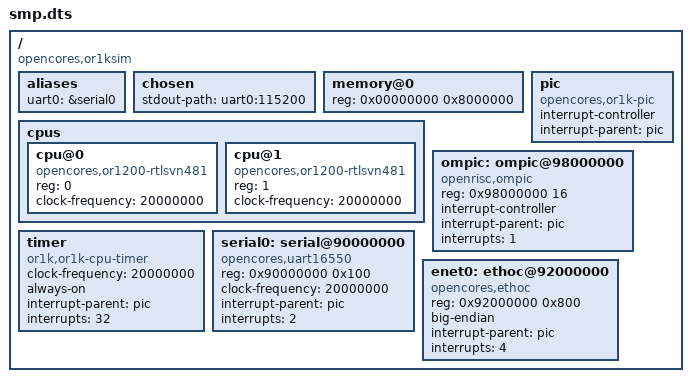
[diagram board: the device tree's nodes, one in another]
/dts-v1/;

/ {
    compatible = "opencores,or1ksim";

    #address-cells = <1>;
    #size-cells = <1>;

    aliases {
        uart0 = &serial0;
    };

    chosen {
        stdout-path = "uart0:115200";
    };

    memory@0 {
        device_type = "memory";
        reg = <0x00000000 0x8000000>;
    };

    cpus {
        #address-cells = <1>;
        #size-cells = <0>;

        cpu@0 {
            compatible = "opencores,or1200-rtlsvn481", "opencores,or1200";
            reg = <0>;
            clock-frequency = <20000000>;
        };

        cpu@1 {
            compatible = "opencores,or1200-rtlsvn481", "opencores,or1200";
            reg = <1>;
            clock-frequency = <20000000>;
        };
    };

    pic: pic {
        compatible = "opencores,or1k-pic";

        interrupt-controller;
        #interrupt-cells = <1>;
        interrupt-parent = <&pic>;
    };

    ompic: ompic@98000000 {
        compatible = "openrisc,ompic";
        reg = <0x98000000 16>;

        interrupt-controller;
        #interrupt-cells = <0>;
        interrupt-parent = <&pic>;
        interrupts = <1>;
    };

    timer {
        compatible = "or1k,or1k-cpu-timer";
        clock-frequency = <20000000>;
        always-on;

        interrupt-parent = <&pic>;
        interrupts = <32>;
    };

    serial0: serial@90000000 {
        compatible = "opencores,uart16550", "ns16550a";
        reg = <0x90000000 0x100>;
        clock-frequency = <20000000>;

        interrupt-parent = <&pic>;
        interrupts = <2>;
    };

    enet0: ethoc@92000000 {
        compatible = "opencores,ethoc";
        reg = <0x92000000 0x800>;
        big-endian;

        interrupt-parent = <&pic>;
        interrupts = <4>;
    };
};
